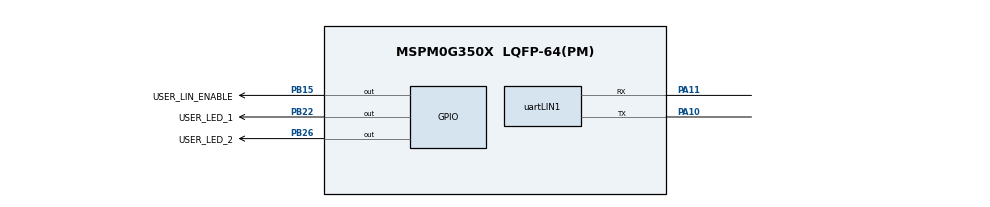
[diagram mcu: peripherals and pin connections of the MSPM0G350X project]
// @cliArgs --device "MSPM0G350X" --package "LQFP-64(PM)" --part "Default"
// @cliArgs --board /ti/boards/LP_MSPM0G3507 --rtos nortos

/**
 * Import the modules used in this configuration.
 */
const Board    = scripting.addModule("/ti/driverlib/Board");
const GPIO     = scripting.addModule("/ti/driverlib/GPIO", {}, false);
const GPIO1    = GPIO.addInstance();
const GPIO2    = GPIO.addInstance();
const SYSCTL   = scripting.addModule("/ti/driverlib/SYSCTL");
const uartLIN  = scripting.addModule("/ti/driverlib/uartLIN", {}, false);
const uartLIN1 = uartLIN.addInstance();

/**
 * Write custom configuration values to the imported modules.
 */

GPIO1.$name                         = "GPIO_LEDS";
GPIO1.port                          = "PORTB";
GPIO1.portSegment                   = "Upper";
GPIO1.associatedPins.create(2);
GPIO1.associatedPins[0].$name       = "USER_LED_1";
GPIO1.associatedPins[0].assignedPin = "22";
GPIO1.associatedPins[0].pin.$assign = "PB22";
GPIO1.associatedPins[1].$name       = "USER_LED_2";
GPIO1.associatedPins[1].assignedPin = "26";
GPIO1.associatedPins[1].pin.$assign = "PB26";

GPIO2.$name                         = "GPIO_LIN_ENABLE";
GPIO2.port                          = "PORTB";
GPIO2.portSegment                   = "Lower";
GPIO2.associatedPins[0].$name       = "USER_LIN_ENABLE";
GPIO2.associatedPins[0].assignedPin = "15";
GPIO2.associatedPins[0].pin.$assign = "PB15";

SYSCTL.clockTreeEn = true;
SYSCTL.forceDefaultClkConfig = true;

uartLIN1.$name                    = "LIN_0";
uartLIN1.profile                  = "CONFIG_PROFILE_1";
uartLIN1.peripheral.rxPin.$assign = "PA11";
uartLIN1.peripheral.txPin.$assign = "PA10";
